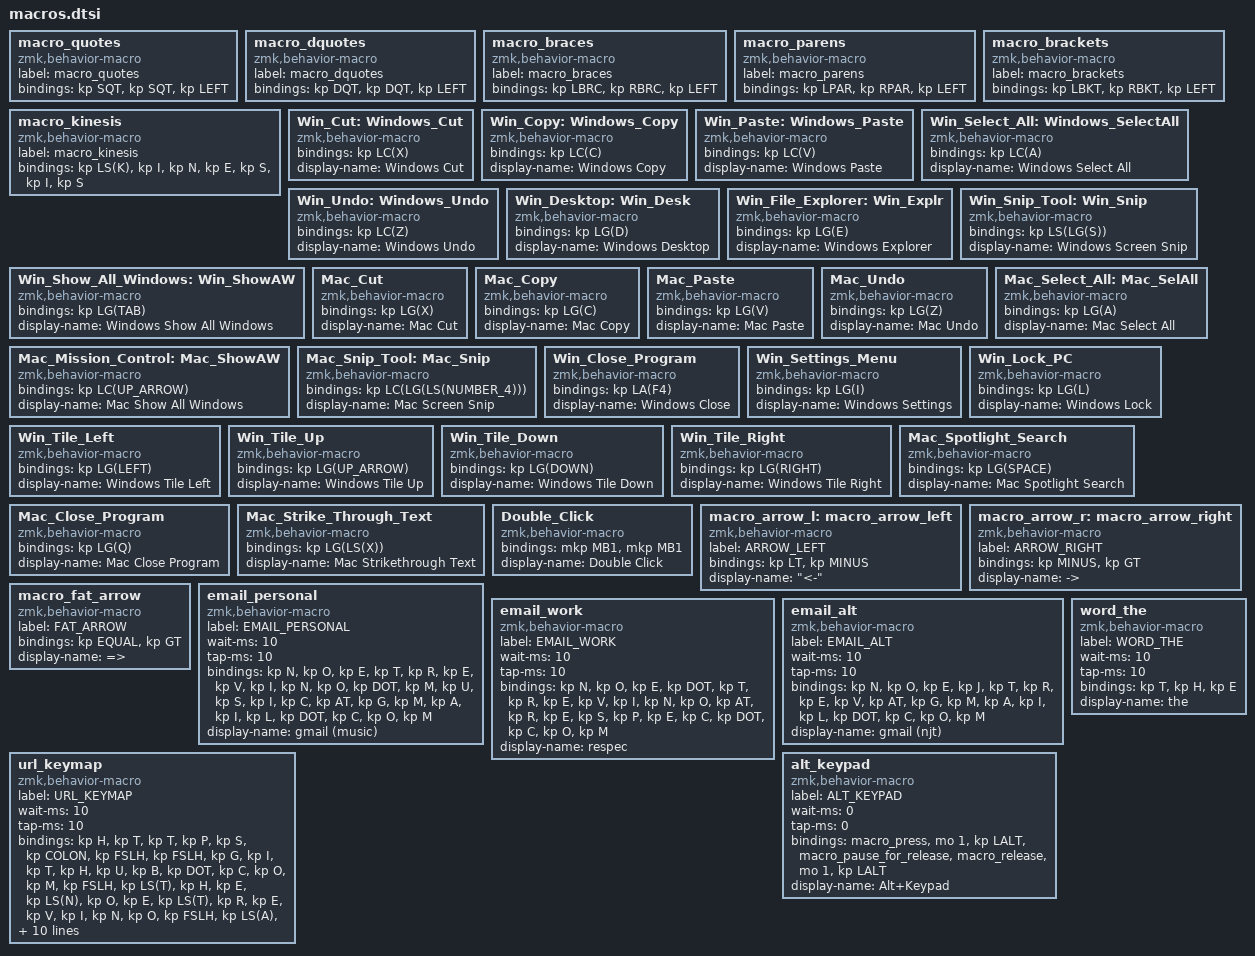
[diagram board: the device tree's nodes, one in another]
  macro_quotes: macro_quotes {
    compatible = "zmk,behavior-macro";
    label = "macro_quotes";
    #binding-cells = <0>;
    bindings = <&kp SQT>, <&kp SQT>, <&kp LEFT>;
  };
  macro_dquotes: macro_dquotes {
    compatible = "zmk,behavior-macro";
    label = "macro_dquotes";
    #binding-cells = <0>;
    bindings = <&kp DQT>, <&kp DQT>, <&kp LEFT>;
  };
  macro_braces: macro_braces {
    compatible = "zmk,behavior-macro";
    label = "macro_braces";
    #binding-cells = <0>;
    bindings = <&kp LBRC>, <&kp RBRC>, <&kp LEFT>;
  };
  macro_parens: macro_parens {
    compatible = "zmk,behavior-macro";
    label = "macro_parens";
    #binding-cells = <0>;
    bindings = <&kp LPAR>, <&kp RPAR>, <&kp LEFT>;
  };
  macro_brackets: macro_brackets {
    compatible = "zmk,behavior-macro";
    label = "macro_brackets";
    #binding-cells = <0>;
    bindings = <&kp LBKT>, <&kp RBKT>, <&kp LEFT>;
  };
  macro_kinesis: macro_kinesis {
    compatible = "zmk,behavior-macro";
    label = "macro_kinesis";
    #binding-cells = <0>;
    bindings = <&kp LS(K)>, <&kp I>, <&kp N>, <&kp E>, <&kp S>, <&kp I>, <&kp S>;
  };
  Win_Cut: Windows_Cut {
    compatible = "zmk,behavior-macro";
    #binding-cells = <0>;
    bindings = <&kp LC(X)>;
    display-name = "Windows Cut";
  };

  Win_Copy: Windows_Copy {
    compatible = "zmk,behavior-macro";
    #binding-cells = <0>;
    bindings = <&kp LC(C)>;
    display-name = "Windows Copy";
  };

  Win_Paste: Windows_Paste {
    compatible = "zmk,behavior-macro";
    #binding-cells = <0>;
    bindings = <&kp LC(V)>;
    display-name = "Windows Paste";
  };

  Win_Select_All: Windows_SelectAll {
      compatible = "zmk,behavior-macro";
      #binding-cells = <0>;
      bindings = <&kp LC(A)>;
      display-name = "Windows Select All";
  };

  Win_Undo: Windows_Undo {
    compatible = "zmk,behavior-macro";
    #binding-cells = <0>;
    bindings = <&kp LC(Z)>;
    display-name = "Windows Undo";
  };

  Win_Desktop: Win_Desk {
    compatible = "zmk,behavior-macro";
    #binding-cells = <0>;
    bindings = <&kp LG(D)>;
    display-name = "Windows Desktop";
  };

  Win_File_Explorer: Win_Explr {
    compatible = "zmk,behavior-macro";
    #binding-cells = <0>;
    bindings = <&kp LG(E)>;
    display-name = "Windows Explorer";
  };

  Win_Snip_Tool: Win_Snip {
    compatible = "zmk,behavior-macro";
    #binding-cells = <0>;
    bindings = <&kp LS(LG(S))>;
    display-name = "Windows Screen Snip";
  };

  Win_Show_All_Windows: Win_ShowAW {
    compatible = "zmk,behavior-macro";
    #binding-cells = <0>;
    bindings = <&kp LG(TAB)>;
    display-name = "Windows Show All Windows";
  };

  Mac_Cut: Mac_Cut {
    compatible = "zmk,behavior-macro";
    #binding-cells = <0>;
    bindings = <&kp LG(X)>;
    display-name = "Mac Cut";
  };

  Mac_Copy: Mac_Copy {
    compatible = "zmk,behavior-macro";
    #binding-cells = <0>;
    bindings = <&kp LG(C)>;
    display-name = "Mac Copy";
  };

  Mac_Paste: Mac_Paste {
    compatible = "zmk,behavior-macro";
    #binding-cells = <0>;
    bindings = <&kp LG(V)>;
    display-name = "Mac Paste";
  };

  Mac_Undo: Mac_Undo {
    compatible = "zmk,behavior-macro";
    #binding-cells = <0>;
    bindings = <&kp LG(Z)>;
    display-name = "Mac Undo";
  };

  Mac_Select_All: Mac_SelAll {
    compatible = "zmk,behavior-macro";
    #binding-cells = <0>;
    bindings = <&kp LG(A)>;
    display-name = "Mac Select All";
  };

  Mac_Mission_Control: Mac_ShowAW {
    compatible = "zmk,behavior-macro";
    #binding-cells = <0>;
    bindings = <&kp LC(UP_ARROW)>;
    display-name = "Mac Show All Windows";
  };

  Mac_Snip_Tool: Mac_Snip {
    compatible = "zmk,behavior-macro";
    #binding-cells = <0>;
    bindings = <&kp LC(LG(LS(NUMBER_4)))>;
    display-name = "Mac Screen Snip";
  };

  Win_Close_Program: Win_Close_Program {
    compatible = "zmk,behavior-macro";
    #binding-cells = <0>;
    bindings = <&kp LA(F4)>;
    display-name = "Windows Close";
  };

  Win_Settings_Menu: Win_Settings_Menu {
    compatible = "zmk,behavior-macro";
    #binding-cells = <0>;
    bindings = <&kp LG(I)>;
    display-name = "Windows Settings";
  };

  Win_Lock_PC: Win_Lock_PC {
    compatible = "zmk,behavior-macro";
    #binding-cells = <0>;
    bindings = <&kp LG(L)>;
    display-name = "Windows Lock";
  };

  Win_Tile_Left: Win_Tile_Left {
    compatible = "zmk,behavior-macro";
    #binding-cells = <0>;
    bindings = <&kp LG(LEFT)>;
    display-name = "Windows Tile Left";
  };

  Win_Tile_Up: Win_Tile_Up {
    compatible = "zmk,behavior-macro";
    #binding-cells = <0>;
    bindings = <&kp LG(UP_ARROW)>;
    display-name = "Windows Tile Up";
  };

  Win_Tile_Down: Win_Tile_Down {
    compatible = "zmk,behavior-macro";
    #binding-cells = <0>;
    bindings = <&kp LG(DOWN)>;
    display-name = "Windows Tile Down";
  };

  Win_Tile_Right: Win_Tile_Right {
    compatible = "zmk,behavior-macro";
    #binding-cells = <0>;
    bindings = <&kp LG(RIGHT)>;
    display-name = "Windows Tile Right";
  };

  Mac_Spotlight_Search: Mac_Spotlight_Search {
    compatible = "zmk,behavior-macro";
    #binding-cells = <0>;
    bindings = <&kp LG(SPACE)>;
    display-name = "Mac Spotlight Search";
  };

  Mac_Close_Program: Mac_Close_Program {
    compatible = "zmk,behavior-macro";
    #binding-cells = <0>;
    bindings = <&kp LG(Q)>;
    display-name = "Mac Close Program";
  };

  Mac_Strike_Through_Text: Mac_Strike_Through_Text {
    compatible = "zmk,behavior-macro";
    #binding-cells = <0>;
    bindings = <&kp LG(LS(X))>;
    display-name = "Mac Strikethrough Text";
  };

  Double_Click: Double_Click {
    compatible = "zmk,behavior-macro";
    #binding-cells = <0>;
    bindings = <&mkp MB1 &mkp MB1>;
    display-name = "Double Click";
  };

  macro_arrow_l: macro_arrow_left {
    compatible = "zmk,behavior-macro";
    label = "ARROW_LEFT";
    #binding-cells = <0>;
    bindings = <&kp LT>, <&kp MINUS>;
    display-name = "<-";
  };

  macro_arrow_r: macro_arrow_right {
    compatible = "zmk,behavior-macro";
    label = "ARROW_RIGHT";
    #binding-cells = <0>;
    bindings = <&kp MINUS>, <&kp GT>;
    display-name = "->";
  };

  macro_fat_arrow: macro_fat_arrow {
    compatible = "zmk,behavior-macro";
    label = "FAT_ARROW";
    #binding-cells = <0>;
    bindings = <&kp EQUAL>, <&kp GT>;
    display-name = "=>";
  };

  // Email macros. wait-ms/tap-ms are lowered from the 30ms default so a ~26
  // character string types in well under half a second instead of ~1.5s.
  // These send US-layout keycodes, so `@` and `.` land correctly only on a
  // US host layout.
  email_personal: email_personal {
    compatible = "zmk,behavior-macro";
    label = "EMAIL_PERSONAL";
    #binding-cells = <0>;
    wait-ms = <10>;
    tap-ms = <10>;
    bindings =
      <&kp N &kp O &kp E &kp T &kp R &kp E &kp V &kp I &kp N &kp O>,
      <&kp DOT &kp M &kp U &kp S &kp I &kp C>,
      <&kp AT &kp G &kp M &kp A &kp I &kp L &kp DOT &kp C &kp O &kp M>;
    display-name = "gmail (music)";
  };

  email_work: email_work {
    compatible = "zmk,behavior-macro";
    label = "EMAIL_WORK";
    #binding-cells = <0>;
    wait-ms = <10>;
    tap-ms = <10>;
    bindings =
      <&kp N &kp O &kp E &kp DOT &kp T &kp R &kp E &kp V &kp I &kp N &kp O>,
      <&kp AT &kp R &kp E &kp S &kp P &kp E &kp C &kp DOT &kp C &kp O &kp M>;
    display-name = "respec";
  };

  email_alt: email_alt {
    compatible = "zmk,behavior-macro";
    label = "EMAIL_ALT";
    #binding-cells = <0>;
    wait-ms = <10>;
    tap-ms = <10>;
    bindings =
      <&kp N &kp O &kp E &kp J &kp T &kp R &kp E &kp V>,
      <&kp AT &kp G &kp M &kp A &kp I &kp L &kp DOT &kp C &kp O &kp M>;
    display-name = "gmail (njt)";
  };

  word_the: word_the {
    compatible = "zmk,behavior-macro";
    label = "WORD_THE";
    #binding-cells = <0>;
    wait-ms = <10>;
    tap-ms = <10>;
    bindings = <&kp T &kp H &kp E>;
    display-name = "the";
  };

  // Types the GitHub blob URL for the rendered keymap so it can be pasted
  // straight into a browser. At 82 characters this queues 164 behaviors,
  // which is why both defconfigs raise CONFIG_ZMK_BEHAVIORS_QUEUE_SIZE to 256.
  url_keymap: url_keymap {
    compatible = "zmk,behavior-macro";
    label = "URL_KEYMAP";
    #binding-cells = <0>;
    wait-ms = <10>;
    tap-ms = <10>;
    bindings =
      <&kp H &kp T &kp T &kp P &kp S &kp COLON &kp FSLH>,
      <&kp FSLH &kp G &kp I &kp T &kp H &kp U &kp B &kp DOT &kp C &kp O &kp M &kp FSLH>,
      <&kp LS(T) &kp H &kp E &kp LS(N) &kp O &kp E &kp LS(T) &kp R &kp E &kp V &kp I &kp N &kp O &kp FSLH>,
      <&kp LS(A) &kp D &kp V &kp N3 &kp N6 &kp N0 &kp MINUS &kp LS(P) &kp R &kp O &kp MINUS &kp LS(Z) &kp LS(M) &kp LS(K) &kp FSLH>,
      <&kp B &kp L &kp O &kp B &kp FSLH>,
      <&kp LS(V) &kp N3 &kp DOT &kp N0 &kp FSLH>,
      <&kp K &kp E &kp Y &kp M &kp A &kp P &kp MINUS &kp D &kp R &kp A &kp W &kp E &kp R &kp FSLH>,
      <&kp A &kp D &kp V &kp N3 &kp N6 &kp N0 &kp DOT &kp S &kp V &kp G>;
    display-name = "keymap url";
  };

  alt_keypad: alt_keypad {
    compatible = "zmk,behavior-macro";
    label = "ALT_KEYPAD";
    #binding-cells = <0>;
    wait-ms = <0>;
    tap-ms = <0>;
    bindings =
      <&macro_press &mo 1 &kp LALT>,
      <&macro_pause_for_release>,
      <&macro_release &mo 1 &kp LALT>;
    display-name = "Alt+Keypad";
  };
